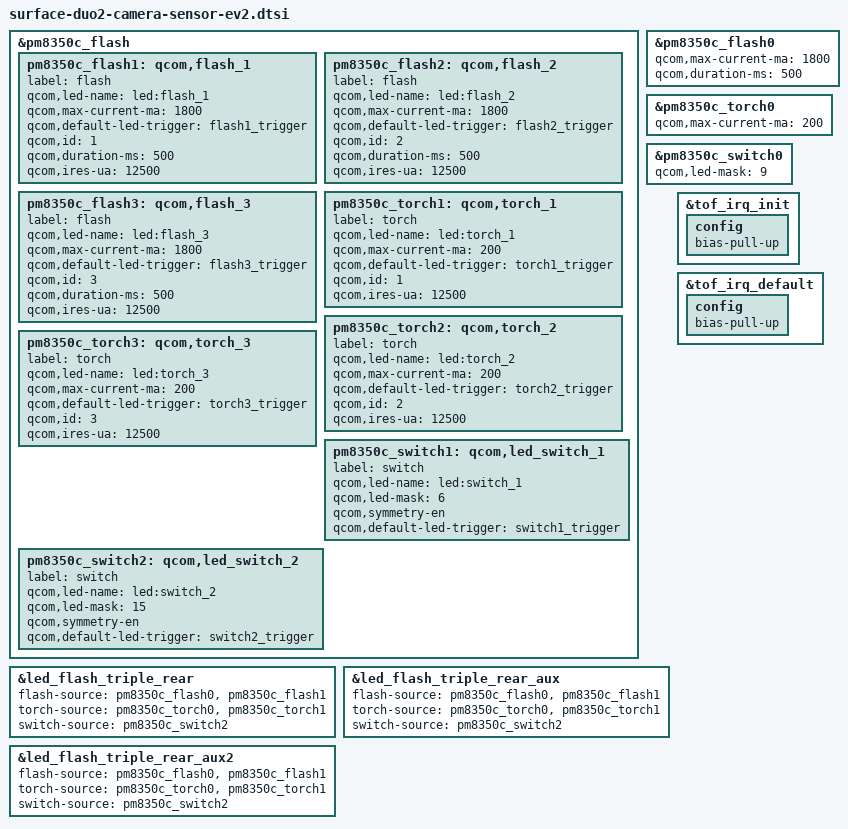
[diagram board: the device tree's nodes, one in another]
/*
 * Copyright (c) 2020 Microsoft Corporation
 *
 * This program is free software; you can redistribute it and/or modify it
 * under the terms of the GNU General Public License version 2 as published by
 * the Free Software Foundation.
 */

/*
 * Camera sensor overlay for EV2
 * NOTE: This is meant to overlay the existing surface-duo2-camera-sensor.dtsi file,
 * which is included in surface-duo2-common.dtsi
 * It includes the dual-led flash related changes.
 */

&pm8350c_flash {
    pm8350c_flash1: qcom,flash_1 {
        label = "flash";
        qcom,led-name = "led:flash_1";
        qcom,max-current-ma = <1800>;
        qcom,default-led-trigger = "flash1_trigger";
        qcom,id = <1>;
        qcom,duration-ms = <500>;
        qcom,ires-ua = <12500>;
    };

    pm8350c_flash2: qcom,flash_2 {
        label = "flash";
        qcom,led-name = "led:flash_2";
        qcom,max-current-ma = <1800>;
        qcom,default-led-trigger = "flash2_trigger";
        qcom,id = <2>;
        qcom,duration-ms = <500>;
        qcom,ires-ua = <12500>;
    };

    pm8350c_flash3: qcom,flash_3 {
        label = "flash";
        qcom,led-name = "led:flash_3";
        qcom,max-current-ma = <1800>;
        qcom,default-led-trigger = "flash3_trigger";
        qcom,id = <3>;
        qcom,duration-ms = <500>;
        qcom,ires-ua = <12500>;
    };

    pm8350c_torch1: qcom,torch_1 {
        label = "torch";
        qcom,led-name = "led:torch_1";
        qcom,max-current-ma = <200>;
        qcom,default-led-trigger = "torch1_trigger";
        qcom,id = <1>;
        qcom,ires-ua = <12500>;
    };

    pm8350c_torch2: qcom,torch_2 {
        label = "torch";
        qcom,led-name = "led:torch_2";
        qcom,max-current-ma = <200>;
        qcom,default-led-trigger = "torch2_trigger";
        qcom,id = <2>;
        qcom,ires-ua = <12500>;
    };

    pm8350c_torch3: qcom,torch_3 {
        label = "torch";
        qcom,led-name = "led:torch_3";
        qcom,max-current-ma = <200>;
        qcom,default-led-trigger = "torch3_trigger";
        qcom,id = <3>;
        qcom,ires-ua = <12500>;
    };

    pm8350c_switch1: qcom,led_switch_1 {
        label = "switch";
        qcom,led-name = "led:switch_1";
        qcom,led-mask = <6>; /* Channels 2 & 3 */
        qcom,symmetry-en;
        qcom,default-led-trigger = "switch1_trigger";
    };

    pm8350c_switch2: qcom,led_switch_2 {
        label = "switch";
        qcom,led-name = "led:switch_2";
        qcom,led-mask = <15>; /* All Channels */
        qcom,symmetry-en;
        qcom,default-led-trigger = "switch2_trigger";
    };
};

&pm8350c_flash0 {
    qcom,max-current-ma = <1800>;
    qcom,duration-ms = <500>;
};

&pm8350c_torch0 {
    qcom,max-current-ma = <200>;
};

&pm8350c_switch0 {
    qcom,led-mask = <9>; /* Channels 1 & 4 */
};

&led_flash_triple_rear {
    flash-source = <&pm8350c_flash0 &pm8350c_flash1>;
    torch-source = <&pm8350c_torch0 &pm8350c_torch1>;
    switch-source = <&pm8350c_switch2>;
};

&led_flash_triple_rear_aux {
    flash-source = <&pm8350c_flash0 &pm8350c_flash1>;
    torch-source = <&pm8350c_torch0 &pm8350c_torch1>;
    switch-source = <&pm8350c_switch2>;
};

&led_flash_triple_rear_aux2 {
    flash-source = <&pm8350c_flash0 &pm8350c_flash1>;
    torch-source = <&pm8350c_torch0 &pm8350c_torch1>;
    switch-source = <&pm8350c_switch2>;
};

/*
 * External pullup is removed (DNS) for TOF interrupt line, hence enable
 * internal pullup for it.
 */
&tof_irq_init {
    config {
        /delete-property/ bias-disable;
        bias-pull-up;
    };
};

&tof_irq_default {
    config {
        /delete-property/ bias-disable;
        bias-pull-up;
    };
};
